AUTOSAR XML (schema 00044)
package /ShAResourceConsumption/SwAddrMethods
  sw addr method CODE: memory-allocation-keyword-policy=ADDR-METHOD-SHORT-NAME, section-type=CODE
  sw addr method VAR_INIT: memory-allocation-keyword-policy=ADDR-METHOD-SHORT-NAME-AND-ALIGNMENT, section-initialization-policy=INIT, section-type=VAR
package /ComponentTypes
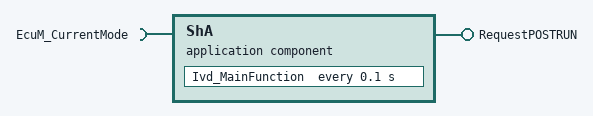
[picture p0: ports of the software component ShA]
  application sw component type ShA
    provide port RequestPOSTRUN: nonqueued-sender-com-spec{data-element=Request, init-value=1}, provided-interface=RequestPOSTRUN
    require port EcuM_CurrentMode: mode-switch-receiver-com-spec{enhanced-mode-api=false, mode-group=currentMode, supports-asynchronous-mode-switch=false}, required-interface=EcuM_CurrentMode
    behavior ShA_InternalBehavior: data-type-mapping=DTMS_ShA
      swc mode switch event MST_Runnable_0: start-on-event=Ivd_CurrentMode_PostRun, activation=ON-ENTRY, mode=EcuM_CurrentMode.currentMode.POST_RUN
      swc mode switch event MST_Ivd_CurrentMode_Run_0: start-on-event=Ivd_CurrentMode_Run, activation=ON-ENTRY, mode=EcuM_CurrentMode.currentMode.RUN
      init event ShA_InitEvent: start-on-event=Ivd_Init
      timing event TMT_Ivd_MainFunction: start-on-event=Ivd_MainFunction, period=0.1
      4 x runnable:
        Ivd_CurrentMode_PostRun
          data-send-points:
            access SEND_RequestPOSTRUN_Request: accessed-variable=RequestPOSTRUN.Request
        Ivd_CurrentMode_Run
          data-send-points:
            access SEND_RequestPOSTRUN_Request: accessed-variable=RequestPOSTRUN.Request
        Ivd_Init
          data-send-points:
            access SEND_RequestPOSTRUN_Request: accessed-variable=RequestPOSTRUN.Request
        Ivd_MainFunction
          data-send-points:
            access SEND_RequestPOSTRUN_Request: accessed-variable=RequestPOSTRUN.Request
  swc implementation ShA_Implementation: vendor-id=75, behavior=ShA_InternalBehavior
    code-descriptors:
      code Default: artifact-descriptors=autosar-engineering-object={short-label=Default, category=SWSRC}
    resource consumption ResourceConsumption
      memory section CODE: sw-addrmethod=CODE
      memory section VAR_INIT_UNSPECIFIED: alignment=UNSPECIFIED, sw-addrmethod=VAR_INIT
package /ComponentTypes/DataTypeMappingSets
  data type mapping set DTMS_ShA: mode-request-type-map{implementation-data-type=uint8, mode-group=EcuM_Mode}
package /DataTypes
  impl type Ivd_RequestPostRun: compu {0=IVD_REQUESTPOSTRUN_REQUESTED, 1=IVD_REQUESTPOSTRUN_RELEASED}, range raw 0..1, implementation-data-type=uint8, type-emitter=RTE
package /ModeDclrGroups
  mode declaration group EcuM_Mode: category=ALPHABETIC_ORDER, initial-mode=STARTUP
    6 x mode:
      POST_RUN
      RUN
      SHUTDOWN
      SLEEP
      STARTUP
      WAKE_SLEEP
package /PortInterfaces
  mode switch interface EcuM_CurrentMode: is-service=true
    mode group currentMode: type=EcuM_Mode
  sender receiver interface RequestPOSTRUN: invalidation-policy{data-element=Request, handle-invalid=DONT-INVALIDATE}
    data Request: type=Ivd_RequestPostRun
